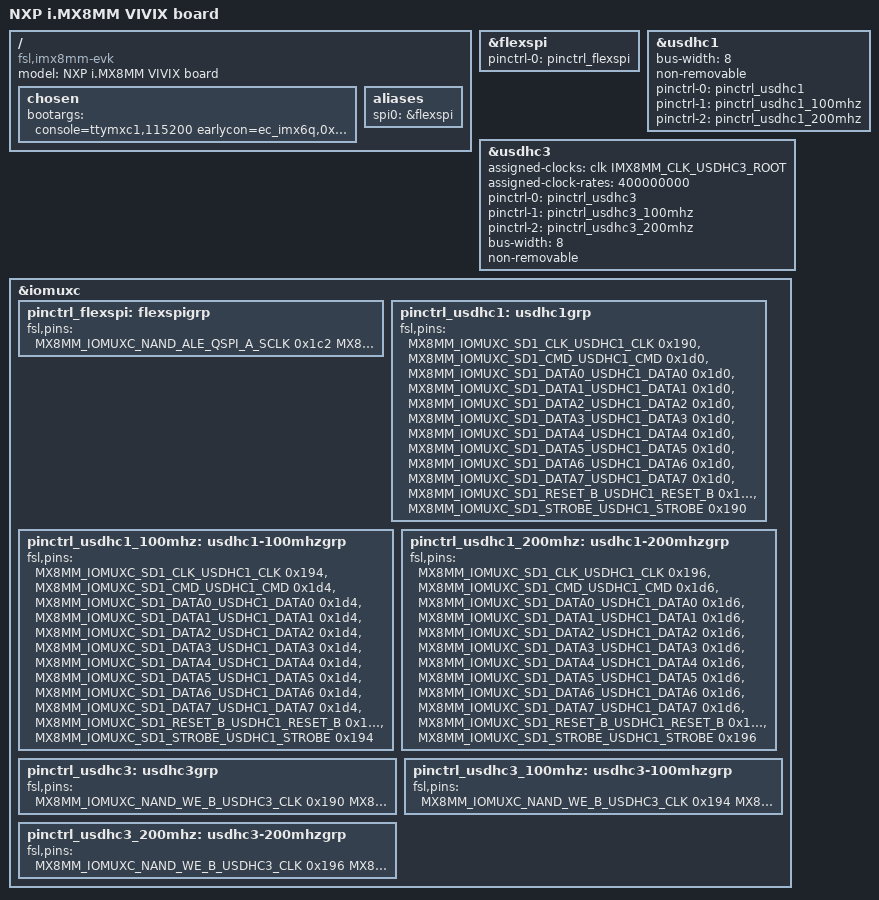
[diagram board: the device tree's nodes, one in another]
// SPDX-License-Identifier: (GPL-2.0+ OR MIT)
/*
 * Copyright 2019-2020 NXP
 */

/dts-v1/;

#include <dt-bindings/usb/pd.h>
#include "imx8mm-vivix.dtsi"

/ {
	model = "NXP i.MX8MM VIVIX board";
	compatible = "fsl,imx8mm-evk", "fsl,imx8mm";

	chosen {
		bootargs = "console=ttymxc1,115200 earlycon=ec_imx6q,0x30890000,115200";
	};

	aliases {
		spi0 = &flexspi;
	};
};

&flexspi {
	pinctrl-names = "default";
	pinctrl-0 = <&pinctrl_flexspi>;
	status = "okay";
};

/* eMMC */
&usdhc1 {
    bus-width = <8>;
    non-removable;
    pinctrl-names = "default", "state_100mhz", "state_200mhz";
    pinctrl-0 = <&pinctrl_usdhc1>;
    pinctrl-1 = <&pinctrl_usdhc1_100mhz>;
    pinctrl-2 = <&pinctrl_usdhc1_200mhz>;
    status = "okay";
};

&usdhc3 {
	assigned-clocks = <&clk IMX8MM_CLK_USDHC3_ROOT>;
	assigned-clock-rates = <400000000>;
	pinctrl-names = "default", "state_100mhz", "state_200mhz";
	pinctrl-0 = <&pinctrl_usdhc3>;
	pinctrl-1 = <&pinctrl_usdhc3_100mhz>;
	pinctrl-2 = <&pinctrl_usdhc3_200mhz>;
	bus-width = <8>;
	non-removable;
	status = "okay";
};

&iomuxc {
	pinctrl_flexspi: flexspigrp {
		fsl,pins = <
			MX8MM_IOMUXC_NAND_ALE_QSPI_A_SCLK               0x1c2
			MX8MM_IOMUXC_NAND_CE0_B_QSPI_A_SS0_B            0x82
			MX8MM_IOMUXC_NAND_DATA00_QSPI_A_DATA0           0x82
			MX8MM_IOMUXC_NAND_DATA01_QSPI_A_DATA1           0x82
			MX8MM_IOMUXC_NAND_DATA02_QSPI_A_DATA2           0x82
			MX8MM_IOMUXC_NAND_DATA03_QSPI_A_DATA3           0x82
			/*
            MX8MM_IOMUXC_NAND_DATA04_QSPI_A_DATA4           0x82
            MX8MM_IOMUXC_NAND_DATA05_QSPI_A_DATA5           0x82
            MX8MM_IOMUXC_NAND_DATA06_QSPI_A_DATA6           0x82
            MX8MM_IOMUXC_NAND_DATA07_QSPI_A_DATA7           0x82
			MX8MM_IOMUXC_NAND_ALE_QSPI_A_SCLK               0xc2
            */

		>;
	};

	pinctrl_usdhc1: usdhc1grp {
        fsl,pins =
            <MX8MM_IOMUXC_SD1_CLK_USDHC1_CLK            0x190>,
            <MX8MM_IOMUXC_SD1_CMD_USDHC1_CMD            0x1d0>,
            <MX8MM_IOMUXC_SD1_DATA0_USDHC1_DATA0        0x1d0>,
            <MX8MM_IOMUXC_SD1_DATA1_USDHC1_DATA1        0x1d0>,
            <MX8MM_IOMUXC_SD1_DATA2_USDHC1_DATA2        0x1d0>,
            <MX8MM_IOMUXC_SD1_DATA3_USDHC1_DATA3        0x1d0>,
            <MX8MM_IOMUXC_SD1_DATA4_USDHC1_DATA4        0x1d0>,
            <MX8MM_IOMUXC_SD1_DATA5_USDHC1_DATA5        0x1d0>,
            <MX8MM_IOMUXC_SD1_DATA6_USDHC1_DATA6        0x1d0>,
            <MX8MM_IOMUXC_SD1_DATA7_USDHC1_DATA7        0x1d0>,
            <MX8MM_IOMUXC_SD1_RESET_B_USDHC1_RESET_B    0x1d1>,
            <MX8MM_IOMUXC_SD1_STROBE_USDHC1_STROBE      0x190>;
    };

    pinctrl_usdhc1_100mhz: usdhc1-100mhzgrp {
        fsl,pins =
            <MX8MM_IOMUXC_SD1_CLK_USDHC1_CLK            0x194>,
            <MX8MM_IOMUXC_SD1_CMD_USDHC1_CMD            0x1d4>,
            <MX8MM_IOMUXC_SD1_DATA0_USDHC1_DATA0        0x1d4>,
            <MX8MM_IOMUXC_SD1_DATA1_USDHC1_DATA1        0x1d4>,
            <MX8MM_IOMUXC_SD1_DATA2_USDHC1_DATA2        0x1d4>,
            <MX8MM_IOMUXC_SD1_DATA3_USDHC1_DATA3        0x1d4>,
            <MX8MM_IOMUXC_SD1_DATA4_USDHC1_DATA4        0x1d4>,
            <MX8MM_IOMUXC_SD1_DATA5_USDHC1_DATA5        0x1d4>,
            <MX8MM_IOMUXC_SD1_DATA6_USDHC1_DATA6        0x1d4>,
            <MX8MM_IOMUXC_SD1_DATA7_USDHC1_DATA7        0x1d4>,
            <MX8MM_IOMUXC_SD1_RESET_B_USDHC1_RESET_B    0x1d1>,
            <MX8MM_IOMUXC_SD1_STROBE_USDHC1_STROBE      0x194>;
    };

    pinctrl_usdhc1_200mhz: usdhc1-200mhzgrp {
        fsl,pins =
            <MX8MM_IOMUXC_SD1_CLK_USDHC1_CLK            0x196>,
            <MX8MM_IOMUXC_SD1_CMD_USDHC1_CMD            0x1d6>,
            <MX8MM_IOMUXC_SD1_DATA0_USDHC1_DATA0        0x1d6>,
            <MX8MM_IOMUXC_SD1_DATA1_USDHC1_DATA1        0x1d6>,
            <MX8MM_IOMUXC_SD1_DATA2_USDHC1_DATA2        0x1d6>,
            <MX8MM_IOMUXC_SD1_DATA3_USDHC1_DATA3        0x1d6>,
            <MX8MM_IOMUXC_SD1_DATA4_USDHC1_DATA4        0x1d6>,
            <MX8MM_IOMUXC_SD1_DATA5_USDHC1_DATA5        0x1d6>,
            <MX8MM_IOMUXC_SD1_DATA6_USDHC1_DATA6        0x1d6>,
            <MX8MM_IOMUXC_SD1_DATA7_USDHC1_DATA7        0x1d6>,
            <MX8MM_IOMUXC_SD1_RESET_B_USDHC1_RESET_B    0x1d1>,
            <MX8MM_IOMUXC_SD1_STROBE_USDHC1_STROBE      0x196>;
    };

	pinctrl_usdhc3: usdhc3grp {
		fsl,pins = <
			MX8MM_IOMUXC_NAND_WE_B_USDHC3_CLK               0x190
			MX8MM_IOMUXC_NAND_WP_B_USDHC3_CMD               0x1d0
			MX8MM_IOMUXC_NAND_DATA04_USDHC3_DATA0           0x1d0
			MX8MM_IOMUXC_NAND_DATA05_USDHC3_DATA1           0x1d0
			MX8MM_IOMUXC_NAND_DATA06_USDHC3_DATA2           0x1d0
			MX8MM_IOMUXC_NAND_DATA06_USDHC3_DATA2           0x1d0
			MX8MM_IOMUXC_NAND_DATA07_USDHC3_DATA3           0x1d0
			MX8MM_IOMUXC_NAND_RE_B_USDHC3_DATA4             0x1d0
			MX8MM_IOMUXC_NAND_CE2_B_USDHC3_DATA5            0x1d0
			MX8MM_IOMUXC_NAND_CE3_B_USDHC3_DATA6            0x1d0
			MX8MM_IOMUXC_NAND_CLE_USDHC3_DATA7              0x1d0
			MX8MM_IOMUXC_NAND_CE1_B_USDHC3_STROBE           0x190
		>;
	};

	pinctrl_usdhc3_100mhz: usdhc3-100mhzgrp {
		fsl,pins = <
			MX8MM_IOMUXC_NAND_WE_B_USDHC3_CLK               0x194
			MX8MM_IOMUXC_NAND_WP_B_USDHC3_CMD               0x1d4
			MX8MM_IOMUXC_NAND_DATA04_USDHC3_DATA0           0x1d4
			MX8MM_IOMUXC_NAND_DATA05_USDHC3_DATA1           0x1d4
			MX8MM_IOMUXC_NAND_DATA06_USDHC3_DATA2           0x1d4
			MX8MM_IOMUXC_NAND_DATA07_USDHC3_DATA3           0x1d4
			MX8MM_IOMUXC_NAND_RE_B_USDHC3_DATA4             0x1d4
			MX8MM_IOMUXC_NAND_CE2_B_USDHC3_DATA5            0x1d4
			MX8MM_IOMUXC_NAND_CE3_B_USDHC3_DATA6            0x1d4
			MX8MM_IOMUXC_NAND_CLE_USDHC3_DATA7              0x1d4
			MX8MM_IOMUXC_NAND_CE1_B_USDHC3_STROBE           0x194
		>;
	};

	pinctrl_usdhc3_200mhz: usdhc3-200mhzgrp {
		fsl,pins = <
			MX8MM_IOMUXC_NAND_WE_B_USDHC3_CLK               0x196
			MX8MM_IOMUXC_NAND_WP_B_USDHC3_CMD               0x1d6
			MX8MM_IOMUXC_NAND_DATA04_USDHC3_DATA0           0x1d6
			MX8MM_IOMUXC_NAND_DATA05_USDHC3_DATA1           0x1d6
			MX8MM_IOMUXC_NAND_DATA06_USDHC3_DATA2           0x1d6
			MX8MM_IOMUXC_NAND_DATA07_USDHC3_DATA3           0x1d6
			MX8MM_IOMUXC_NAND_RE_B_USDHC3_DATA4             0x1d6
			MX8MM_IOMUXC_NAND_CE2_B_USDHC3_DATA5            0x1d6
			MX8MM_IOMUXC_NAND_CE3_B_USDHC3_DATA6            0x1d6
			MX8MM_IOMUXC_NAND_CLE_USDHC3_DATA7              0x1d6
			MX8MM_IOMUXC_NAND_CE1_B_USDHC3_STROBE           0x196
		>;
	};
};
